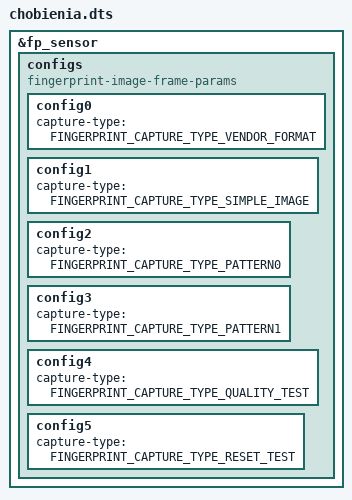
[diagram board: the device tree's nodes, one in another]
/* Copyright 2026 The ChromiumOS Authors.
 * Use of this source code is governed by a BSD-style license that can be
 * found in the LICENSE file.
 */

#include "common.dtsi"

#define FT9849_COMMON_IMAGE_PROPS \
	width = <80>; \
	height = <128>; \
	bits-per-pixel = <12>; \
	frame-size = <30720>; \
	image-data-offset-bytes = <0>; \
	v4l2-pixel-format = "V4L2_PIX_FMT_GREY";

&fp_sensor {
	configs {
		compatible = "fingerprint-image-frame-params";
		config0 {
			FT9849_COMMON_IMAGE_PROPS
			capture-type = "FINGERPRINT_CAPTURE_TYPE_VENDOR_FORMAT";
		};
		config1 {
			FT9849_COMMON_IMAGE_PROPS
			capture-type = "FINGERPRINT_CAPTURE_TYPE_SIMPLE_IMAGE";
		};
		config2 {
			FT9849_COMMON_IMAGE_PROPS
			capture-type = "FINGERPRINT_CAPTURE_TYPE_PATTERN0";
		};
		config3 {
			FT9849_COMMON_IMAGE_PROPS
			capture-type = "FINGERPRINT_CAPTURE_TYPE_PATTERN1";
		};
		config4 {
			FT9849_COMMON_IMAGE_PROPS
			capture-type = "FINGERPRINT_CAPTURE_TYPE_QUALITY_TEST";
		};
		config5 {
			FT9849_COMMON_IMAGE_PROPS
			capture-type = "FINGERPRINT_CAPTURE_TYPE_RESET_TEST";
		};
	};
};
